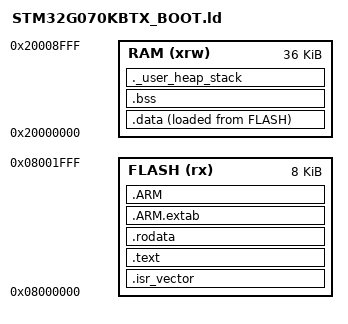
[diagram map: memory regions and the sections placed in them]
/* STM32G070KBTX_BOOT.ld — Bootloader linker script
 * FLASH: 0x08000000, 8 KB  (pages 0-3)
 * RAM  : 0x20000000, 36 KB (same as app — bootloader uses bottom of RAM)
 */

ENTRY(Reset_Handler)

/* Stack top — required by startup_stm32g071xx.o */
_estack = ORIGIN(RAM) + LENGTH(RAM);

MEMORY
{
  RAM   (xrw) : ORIGIN = 0x20000000, LENGTH = 36K
  FLASH  (rx) : ORIGIN = 0x08000000, LENGTH = 8K
}

SECTIONS
{
  .isr_vector :
  {
    . = ALIGN(4);
    KEEP(*(.isr_vector))
    . = ALIGN(4);
  } >FLASH

  .text :
  {
    . = ALIGN(4);
    *(.text)
    *(.text*)
    *(.glue_7)
    *(.glue_7t)
    *(.eh_frame)
    KEEP(*(.init))
    KEEP(*(.fini))
    . = ALIGN(4);
    _etext = .;
  } >FLASH

  .rodata :
  {
    . = ALIGN(4);
    *(.rodata)
    *(.rodata*)
    . = ALIGN(4);
  } >FLASH

  .ARM.extab : { *(.ARM.extab* .gnu.linkonce.armextab.*) } >FLASH
  .ARM        : { __exidx_start = .; *(.ARM.exidx*) __exidx_end = .; } >FLASH

  _sidata = LOADADDR(.data);

  .data :
  {
    . = ALIGN(4);
    _sdata = .;
    *(.data)
    *(.data*)
    . = ALIGN(4);
    _edata = .;
  } >RAM AT>FLASH

  .bss :
  {
    . = ALIGN(4);
    _sbss = .;
    __bss_start__ = _sbss;
    *(.bss)
    *(.bss*)
    *(COMMON)
    . = ALIGN(4);
    _ebss = .;
    __bss_end__ = _ebss;
  } >RAM

  ._user_heap_stack :
  {
    . = ALIGN(8);
    PROVIDE ( end = . );
    PROVIDE ( _end = . );
    . = . + 0x400;   /* 1 KB heap */
    . = . + 0x400;   /* 1 KB stack */
    . = ALIGN(8);
  } >RAM

  /DISCARD/ :
  {
    libc.a ( * )
    libm.a ( * )
    libgcc.a ( * )
  }

  .ARM.attributes 0 : { *(.ARM.attributes) }
}
